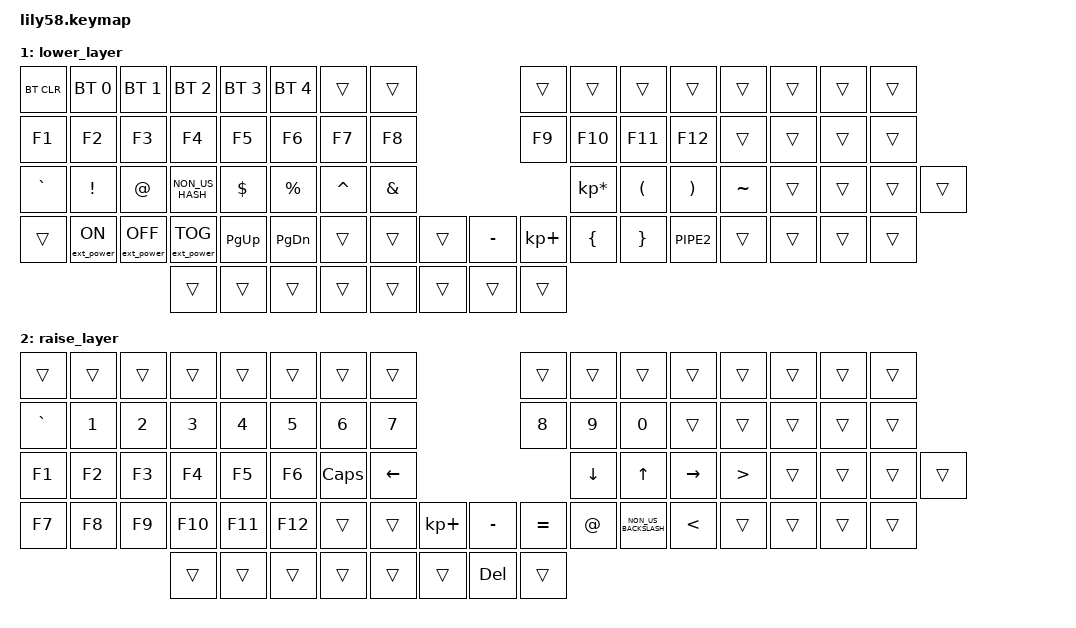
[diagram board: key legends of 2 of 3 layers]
/*
 * Copyright (c) 2020 The ZMK Contributors
 *
 * SPDX-License-Identifier: MIT
 */

#include <behaviors.dtsi>
#include <dt-bindings/zmk/keys.h>
#include <dt-bindings/zmk/bt.h>
#include <dt-bindings/zmk/ext_power.h>

/ {

	// behaviors {
    //     caps: caps_on {
    //         compatible = "zmk,behavior-tap-dance";
    //         label = "CAPS_ON";
    //         #binding-cells = <0>;
    //         tapping-term-ms = <200>;
    //         bindings = <&kp LCTRL>, <&kp CAPSLOCK>;
    //     };
    // };

	sensors {
		compatible = "zmk,keymap-sensors";
		sensors = <&encoder_1_top_row>;
	};
	keymap {
		compatible = "zmk,keymap";

		default_layer {
// ------------------------------------------------------------------------------------------------------------
// |  ESC  |  1  |  2  |  3   |  4   |  5   |                   |  6   |  7    |  8    |  9   |   0   |   `   |
// |  TAB  |  Q  |  W  |  E   |  R   |  T   |                   |  Y   |  U    |  I    |  O   |   P   |   -   |
// |   '   |  A  |  S  |  D   |  F   |  G   |                   |  H   |  J    |  K    |  L   |   ;   |  LCTRL |
// | SHIFT |  Z  |  X  |  C   |  V   |  B   |   "["  |  |  "]"  |  N   |  M    |  ,    |  .   |   /   | SHIFT |
//                     | GUI  | ALT  | RAISE|  SPACE |  | ENTER | LOWER| BSPC  | GUI   |
			bindings = <
&kp ESC   &kp N1 &kp N2 &kp N3   &kp N4   &kp N5                     &kp N6 &kp N7   &kp N8    &kp N9  &kp N0   &kp GRAVE 	 &kp &none       &kp KP_NUMLOCK  &kp KP_ASTERISK &kp KP_MINUS    
&kp TAB   &kp Q  &kp W  &kp E    &kp R    &kp T                      &kp Y  &kp U    &kp I     &kp O   &kp P    &kp MINUS	 &kp KP_NUMBER_7 &kp KP_NUMBER_8 &kp KP_NUMBER_9 &kp KP_PLUS
&kp SQT   &kp A  &kp S  &kp D    &kp F    &kp G                      &kp H  &kp J    &kp K     &kp L   &kp SEMI &kp LCTRL	 &kp KP_NUMBER_4 &kp KP_NUMBER_5 &kp KP_NUMBER_6 &kp &none
&kp LSHFT &kp Z  &kp X  &kp C    &kp V    &kp B  &kp LBKT   &kp RBKT &kp N  &kp M    &kp COMMA &kp DOT &kp FSLH &kp RSHFT	 &kp KP_NUMBER_1 &kp KP_NUMBER_2 &kp KP_NUMBER_3 &lt 1 KP_ENTER
                        &kp LGUI &kp LALT &mo 2  &kp SPACE  &kp RET  &mo 1  &kp BSPC &kp RGUI								 &kp KP_NUMBER_0 &kp KP_NUMBER_0 &kp KP_DOT &lt 1 KP_ENTER	
			>;

			sensor-bindings = <&inc_dec_kp PG_UP PG_DN>;
		};

		lower_layer {
// ------------------------------------------------------------------------------------------------------------
// | BTCLR | BT1 | BT2 |  BT3 |  BT4 |  BT5 |                   |      |       |       |      |       |       |
// |  F1   |  F2 |  F3 |  F4  |  F5  |  F6  |                   |  F7  |  F8   |  F9   |  F10 |  F11  |  F12  |
// |   `   |  !  |  @  |  #   |  $   |  %   |                   |  ^   |  &    |  *    |  (   |   )   |   ~   |
// |       |     |     |      | PG_UP| PG_DN|        |  |       |      |  _    |  +    |  {   |   }   |  "|"  |
//                     |      |      |      |        |  |       |      |       |       |
			bindings = <
&bt BT_CLR &bt BT_SEL 0     &bt BT_SEL 1      &bt BT_SEL 2      &bt BT_SEL 3 &bt BT_SEL 4                 &trans    &trans    &trans          &trans    &trans    &trans				&trans	  &trans    &trans    &trans
&kp F1     &kp F2           &kp F3            &kp F4            &kp F5       &kp F6                       &kp F7    &kp F8    &kp F9          &kp F10   &kp F11   &kp F12				&trans    &trans    &trans    &trans
&kp GRAVE  &kp EXCL         &kp AT            &kp NON_US_HASH         &kp DOLLAR   &kp PRCNT                    &kp CARET &kp AMPS  &kp KP_MULTIPLY &kp LPAR  &kp RPAR  &kp TILDE		&trans    &trans    &trans    &trans
&trans     &ext_power EP_ON &ext_power EP_OFF &ext_power EP_TOG &kp PG_UP    &kp PG_DN    &trans   &trans &trans &kp MINUS    &kp KP_PLUS     &kp LBRC  &kp RBRC  &kp PIPE2				&trans    &trans    &trans    &trans
                                              &trans            &trans       &trans    &trans   &trans    &trans &trans    &trans
			>;

			sensor-bindings = <&inc_dec_kp C_VOL_UP C_VOL_DN>;
		};

		raise_layer {
// ------------------------------------------------------------------------------------------------------------
// |       |     |     |      |      |      |                   |      |       |       |      |       |       |
// |   `   |  1  |  2  |  3   |  4   |  5   |                   |  6   |   7   |   8   |  9   |   0   |       |
// |   F1  |  F2 |  F3 |  F4  |  F5  |  F6  |                   | CAPS |   <-  |   v   |  ^   |  ->   |  ">"  |
// |   F7  |  F8 |  F9 |  F10 |  F11 |  F12 |        |  |       |  +   |   -   |   =   |  "   |   \   |  "<"  |
//                     |      |      |      |        |  |       |      |  DEL  |       |
			bindings = <
&trans    &trans &trans &trans  &trans  &trans                       &trans      &trans    &trans    &trans   &trans    &trans						 	&trans	  &trans    &trans    &trans
&kp GRAVE &kp N1 &kp N2 &kp N3  &kp N4  &kp N5                       &kp N6      &kp N7    &kp N8    &kp N9   &kp N0    &trans							&trans    &trans    &trans    &trans
&kp F1    &kp F2 &kp F3 &kp F4  &kp F5  &kp F6                       &kp CAPS      &kp LEFT  &kp DOWN  &kp UP   &kp RIGHT &kp GREATER_THAN				&trans    &trans    &trans    &trans
&kp F7    &kp F8 &kp F9 &kp F10 &kp F11 &kp F12   &trans   &trans    &kp KP_PLUS &kp MINUS &kp EQUAL &kp AT_SIGN &kp NON_US_BACKSLASH  &kp LESS_THAN	&trans    &trans    &trans    &trans
                        &trans  &trans  &trans    &trans   &trans    &trans      &kp DELETE    &trans
			>;

			sensor-bindings = <&inc_dec_kp C_VOL_UP C_VOL_DN>;
		};
	};
};
